# STM32F7x6 register map
File version: 1.3
CPU: CM7 r0p0, little endian, no MPU, no FPU, 3 interrupt priority bits
Registers are 32-bit, read-write, reset 0x0 unless marked. A register's access mark holds for its fields unless they carry their own. Offsets are from the block's base; [hi:lo] are bit positions; {n}, {i} and the like mark numbered series; 'fields as' and 'values as' point back to an identical list.

## OTG_FS_GLOBAL — USB on the go full speed
Base 0x50000000
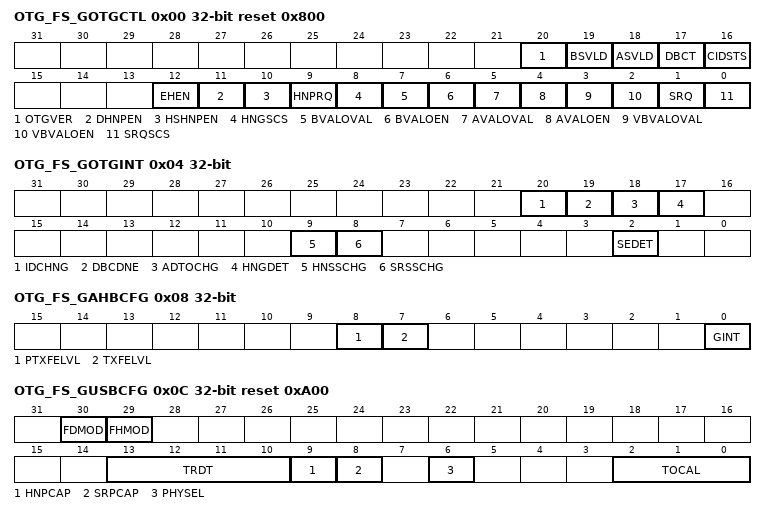
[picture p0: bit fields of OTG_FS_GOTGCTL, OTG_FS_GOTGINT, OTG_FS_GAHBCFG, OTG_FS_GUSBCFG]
0x00 OTG_FS_GOTGCTL access per field reset 0x800 — OTG_FS control and status register (OTG_FS_GOTGCTL)
  [20] OTGVER rw — OTG version
  [19] BSVLD ro — B-session valid
  [18] ASVLD ro — A-session valid
  [17] DBCT ro — Long/short debounce time
  [16] CIDSTS ro — Connector ID status
  [12] EHEN rw — Embedded host enable
  [11] DHNPEN rw — Device HNP enabled
  [10] HSHNPEN rw — Host set HNP enable
  [9] HNPRQ rw — HNP request
  [8] HNGSCS ro — Host negotiation success
  [7] BVALOVAL rw — B-peripheral session valid override value
  [6] BVALOEN rw — B-peripheral session valid override enable
  [5] AVALOVAL rw — A-peripheral session valid override value
  [4] AVALOEN rw — A-peripheral session valid override enable
  [3] VBVALOVAL rw — VBUS valid override value
  [2] VBVALOEN rw — VBUS valid override enable
  [1] SRQ rw — Session request
  [0] SRQSCS ro — Session request success
0x04 OTG_FS_GOTGINT — OTG_FS interrupt register (OTG_FS_GOTGINT)
  [20] IDCHNG — ID input pin changed
  [19] DBCDNE — Debounce done
  [18] ADTOCHG — A-device timeout change
  [17] HNGDET — Host negotiation detected
  [9] HNSSCHG — Host negotiation success status change
  [8] SRSSCHG — Session request success status change
  [2] SEDET — Session end detected
0x08 OTG_FS_GAHBCFG — OTG_FS AHB configuration register (OTG_FS_GAHBCFG)
  [8] PTXFELVL — Periodic TxFIFO empty level
  [7] TXFELVL — TxFIFO empty level
  [0] GINT — Global interrupt mask
0x0C OTG_FS_GUSBCFG access per field reset 0xA00 — OTG_FS USB configuration register (OTG_FS_GUSBCFG)
  [30] FDMOD rw — Force device mode
  [29] FHMOD rw — Force host mode
  [13:10] TRDT rw — USB turnaround time
  [9] HNPCAP rw — HNP-capable
  [8] SRPCAP rw — SRP-capable
  [6] PHYSEL wo — Full Speed serial transceiver select
  [2:0] TOCAL rw — FS timeout calibration
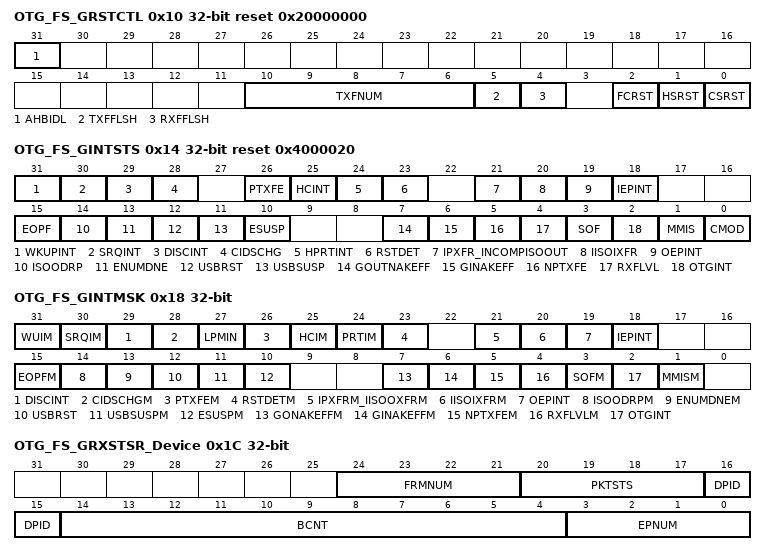
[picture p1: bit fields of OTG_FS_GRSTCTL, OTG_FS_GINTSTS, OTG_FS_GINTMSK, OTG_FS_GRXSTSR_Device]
0x10 OTG_FS_GRSTCTL access per field reset 0x20000000 — OTG_FS reset register (OTG_FS_GRSTCTL)
  [31] AHBIDL ro — AHB master idle
  [10:6] TXFNUM rw — TxFIFO number
  [5] TXFFLSH rw — TxFIFO flush
  [4] RXFFLSH rw — RxFIFO flush
  [2] FCRST rw — Host frame counter reset
  [1] HSRST rw — HCLK soft reset
  [0] CSRST rw — Core soft reset
0x14 OTG_FS_GINTSTS access per field reset 0x4000020 — OTG_FS core interrupt register (OTG_FS_GINTSTS)
  [31] WKUPINT rw — Resume/remote wakeup detected interrupt
  [30] SRQINT rw — Session request/new session detected interrupt
  [29] DISCINT rw — Disconnect detected interrupt
  [28] CIDSCHG rw — Connector ID status change
  [26] PTXFE ro — Periodic TxFIFO empty
  [25] HCINT ro — Host channels interrupt
  [24] HPRTINT ro — Host port interrupt
  [23] RSTDET rw — Reset detected interrupt
  [21] IPXFR_INCOMPISOOUT rw — Incomplete periodic transfer(Host mode)/Incomplete isochronous OUT transfer(Device mode)
  [20] IISOIXFR rw — Incomplete isochronous IN transfer
  [19] OEPINT ro — OUT endpoint interrupt
  [18] IEPINT ro — IN endpoint interrupt
  [15] EOPF rw — End of periodic frame interrupt
  [14] ISOODRP rw — Isochronous OUT packet dropped interrupt
  [13] ENUMDNE rw — Enumeration done
  [12] USBRST rw — USB reset
  [11] USBSUSP rw — USB suspend
  [10] ESUSP rw — Early suspend
  [7] GOUTNAKEFF ro — Global OUT NAK effective
  [6] GINAKEFF ro — Global IN non-periodic NAK effective
  [5] NPTXFE ro — Non-periodic TxFIFO empty
  [4] RXFLVL ro — RxFIFO non-empty
  [3] SOF rw — Start of frame
  [2] OTGINT ro — OTG interrupt
  [1] MMIS rw — Mode mismatch interrupt
  [0] CMOD ro — Current mode of operation
0x18 OTG_FS_GINTMSK access per field — OTG_FS interrupt mask register (OTG_FS_GINTMSK)
  [31] WUIM rw — Resume/remote wakeup detected interrupt mask
  [30] SRQIM rw — Session request/new session detected interrupt mask
  [29] DISCINT rw — Disconnect detected interrupt mask
  [28] CIDSCHGM rw — Connector ID status change mask
  [27] LPMIN rw — LPM interrupt mask
  [26] PTXFEM rw — Periodic TxFIFO empty mask
  [25] HCIM rw — Host channels interrupt mask
  [24] PRTIM ro — Host port interrupt mask
  [23] RSTDETM rw — Reset detected interrupt mask
  [21] IPXFRM_IISOOXFRM rw — Incomplete periodic transfer mask(Host mode)/Incomplete isochronous OUT transfer mask(Device mode)
  [20] IISOIXFRM rw — Incomplete isochronous IN transfer mask
  [19] OEPINT rw — OUT endpoints interrupt mask
  [18] IEPINT rw — IN endpoints interrupt mask
  [15] EOPFM rw — End of periodic frame interrupt mask
  [14] ISOODRPM rw — Isochronous OUT packet dropped interrupt mask
  [13] ENUMDNEM rw — Enumeration done mask
  [12] USBRST rw — USB reset mask
  [11] USBSUSPM rw — USB suspend mask
  [10] ESUSPM rw — Early suspend mask
  [7] GONAKEFFM rw — Global OUT NAK effective mask
  [6] GINAKEFFM rw — Global non-periodic IN NAK effective mask
  [5] NPTXFEM rw — Non-periodic TxFIFO empty mask
  [4] RXFLVLM rw — Receive FIFO non-empty mask
  [3] SOFM rw — Start of frame mask
  [2] OTGINT rw — OTG interrupt mask
  [1] MMISM rw — Mode mismatch interrupt mask
0x1C OTG_FS_GRXSTSR_Device ro — OTG_FS Receive status debug read(Device mode)
  [24:21] FRMNUM — Frame number
  [20:17] PKTSTS — Packet status
  [16:15] DPID — Data PID
  [14:4] BCNT — Byte count
  [3:0] EPNUM — Endpoint number
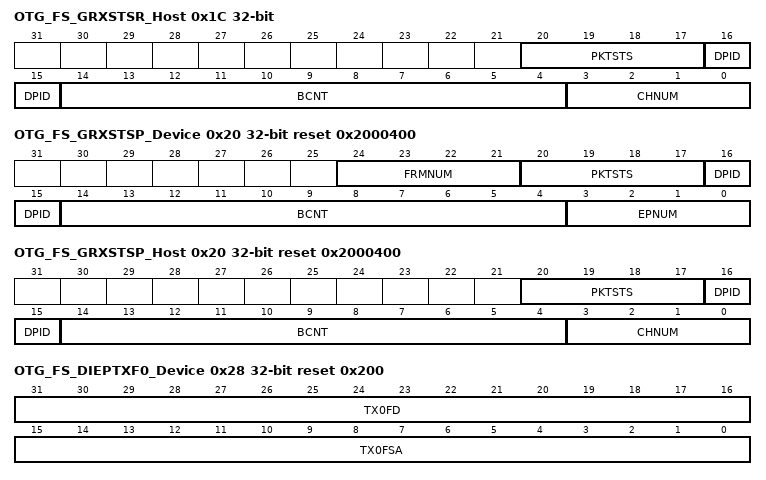
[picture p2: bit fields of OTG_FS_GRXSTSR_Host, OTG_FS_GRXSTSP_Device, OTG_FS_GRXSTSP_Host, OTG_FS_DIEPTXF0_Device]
0x1C OTG_FS_GRXSTSR_Host ro (alternate view of OTG_FS_GRXSTSR_Device) — OTG_FS Receive status debug read(Host mode)
  [20:17] PKTSTS — Packet status
  [16:15] DPID — Data PID
  [14:4] BCNT — Byte count
  [3:0] CHNUM — Endpoint number
0x20 OTG_FS_GRXSTSP_Device ro reset 0x2000400 — OTG status read and pop register (Device mode)
  fields as OTG_FS_GRXSTSR_Device
0x20 OTG_FS_GRXSTSP_Host ro reset 0x2000400 (alternate view of OTG_FS_GRXSTSP_Device) — OTG status read and pop register (Host mode)
  [20:17] PKTSTS — Packet status
  [16:15] DPID — Data PID
  [14:4] BCNT — Byte count
  [3:0] CHNUM — Channel number
0x24 OTG_FS_GRXFSIZ reset 0x200 — OTG_FS Receive FIFO size register (OTG_FS_GRXFSIZ)
  [15:0] RXFD — RxFIFO depth
0x28 OTG_FS_DIEPTXF0_Device reset 0x200 — OTG_FS Endpoint 0 Transmit FIFO size
  [31:16] TX0FD — Endpoint 0 TxFIFO depth
  [15:0] TX0FSA — Endpoint 0 transmit RAM start address
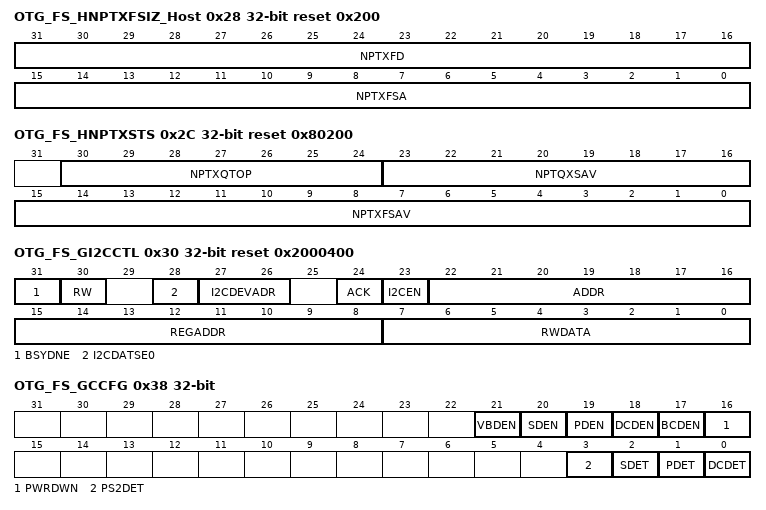
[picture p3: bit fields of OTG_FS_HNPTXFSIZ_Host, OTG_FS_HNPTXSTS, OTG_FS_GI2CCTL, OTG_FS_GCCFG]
0x28 OTG_FS_HNPTXFSIZ_Host reset 0x200 (alternate view of OTG_FS_DIEPTXF0_Device) — OTG_FS Host non-periodic transmit FIFO size register
  [31:16] NPTXFD — Non-periodic TxFIFO depth
  [15:0] NPTXFSA — Non-periodic transmit RAM start address
0x2C OTG_FS_HNPTXSTS ro reset 0x80200 — OTG_FS non-periodic transmit FIFO/queue status register (OTG_FS_GNPTXSTS)
  [30:24] NPTXQTOP — Top of the non-periodic transmit request queue
  [23:16] NPTQXSAV — Non-periodic transmit request queue space available
  [15:0] NPTXFSAV — Non-periodic TxFIFO space available
0x30 OTG_FS_GI2CCTL reset 0x2000400 — OTG I2C access register
  [31] BSYDNE — I2C Busy/Done
  [30] RW — Read/Write Indicator
  [28] I2CDATSE0 — I2C DatSe0 USB mode
  [27:26] I2CDEVADR — I2C Device Address
  [24] ACK — I2C ACK
  [23] I2CEN — I2C Enable
  [22:16] ADDR — I2C Address
  [15:8] REGADDR — I2C Register Address
  [7:0] RWDATA — I2C Read/Write Data
0x38 OTG_FS_GCCFG — OTG_FS general core configuration register (OTG_FS_GCCFG)
  [21] VBDEN — USB VBUS detection enable
  [20] SDEN — Secondary detection (SD) mode enable
  [19] PDEN — Primary detection (PD) mode enable
  [18] DCDEN — Data contact detection (DCD) mode enable
  [17] BCDEN — Battery charging detector (BCD) enable
  [16] PWRDWN — Power down
  [3] PS2DET — DM pull-up detection status
  [2] SDET — Secondary detection (SD) status
  [1] PDET — Primary detection (PD) status
  [0] DCDET — Data contact detection (DCD) status
0x3C OTG_FS_CID reset 0x1000 — core ID register
  [31:0] PRODUCT_ID
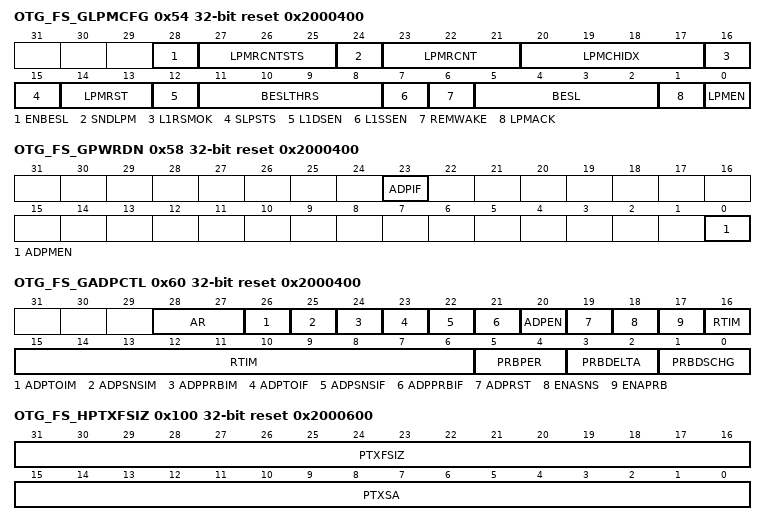
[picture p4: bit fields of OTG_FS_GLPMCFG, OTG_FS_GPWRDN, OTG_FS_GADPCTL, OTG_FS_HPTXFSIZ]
0x54 OTG_FS_GLPMCFG access per field reset 0x2000400 — OTG core LPM configuration register
  [28] ENBESL rw — Enable best effort service latency
  [27:25] LPMRCNTSTS ro — LPM retry count status
  [24] SNDLPM rw — Send LPM transaction
  [23:21] LPMRCNT rw — LPM retry count
  [20:17] LPMCHIDX rw — LPM Channel Index
  [16] L1RSMOK ro — Sleep State Resume OK
  [15] SLPSTS ro — Port sleep status
  [14:13] LPMRST ro — LPM response
  [12] L1DSEN rw — L1 deep sleep enable
  [11:8] BESLTHRS rw — BESL threshold
  [7] L1SSEN rw — L1 Shallow Sleep enable
  [6] REMWAKE rw — bRemoteWake value
  [5:2] BESL rw — Best effort service latency
  [1] LPMACK rw — LPM token acknowledge enable
  [0] LPMEN rw — LPM support enable
0x58 OTG_FS_GPWRDN reset 0x2000400 — OTG power down register
  [23] ADPIF — ADP interrupt flag
  [0] ADPMEN — ADP module enable
0x60 OTG_FS_GADPCTL access per field reset 0x2000400 — OTG ADP timer, control and status register
  [28:27] AR rw — Access request
  [26] ADPTOIM rw — ADP timeout interrupt mask
  [25] ADPSNSIM rw — ADP sense interrupt mask
  [24] ADPPRBIM rw — ADP probe interrupt mask
  [23] ADPTOIF rw — ADP timeout interrupt flag
  [22] ADPSNSIF rw — ADP sense interrupt flag
  [21] ADPPRBIF rw — ADP probe interrupt flag
  [20] ADPEN rw — ADP enable
  [19] ADPRST ro — ADP reset
  [18] ENASNS rw — Enable sense
  [17] ENAPRB rw — Enable probe
  [16:6] RTIM ro — Ramp time
  [5:4] PRBPER rw — Probe period
  [3:2] PRBDELTA rw — Probe delta
  [1:0] PRBDSCHG rw — Probe discharge
0x100 OTG_FS_HPTXFSIZ reset 0x2000600 — OTG_FS Host periodic transmit FIFO size register (OTG_FS_HPTXFSIZ)
  [31:16] PTXFSIZ — Host periodic TxFIFO depth
  [15:0] PTXSA — Host periodic TxFIFO start address
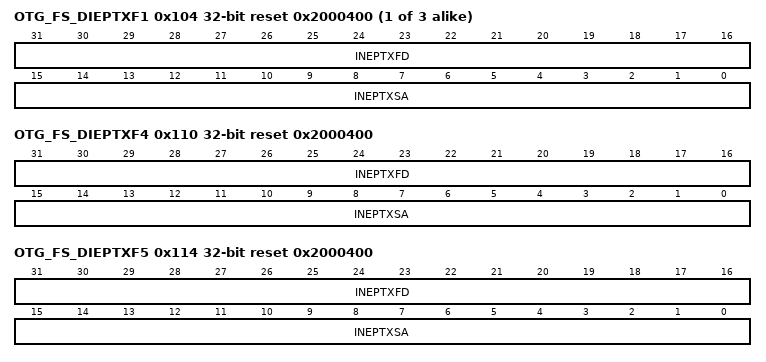
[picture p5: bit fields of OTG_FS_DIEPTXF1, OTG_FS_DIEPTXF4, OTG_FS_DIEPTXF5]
{0x100+4i} OTG_FS_DIEPTXF{i} reset 0x2000400 (i=1..3) — OTG_FS device IN endpoint transmit FIFO size register (OTG_FS_DIEPTXF{i})
  [31:16] INEPTXFD — IN endpoint TxFIFO depth
  [15:0] INEPTXSA — IN endpoint FIFO{i+1} transmit RAM start address
0x110 OTG_FS_DIEPTXF4 reset 0x2000400 — OTG_FS device IN endpoint transmit FIFO size register (OTG_FS_DIEPTXF4)
  [31:16] INEPTXFD — IN endpoint Tx FIFO depth
  [15:0] INEPTXSA — IN endpoint FIFOx transmit RAM start address
0x114 OTG_FS_DIEPTXF5 reset 0x2000400 — OTG_FS device IN endpoint transmit FIFO size register (OTG_FS_DIEPTXF5)
  fields as OTG_FS_DIEPTXF4
